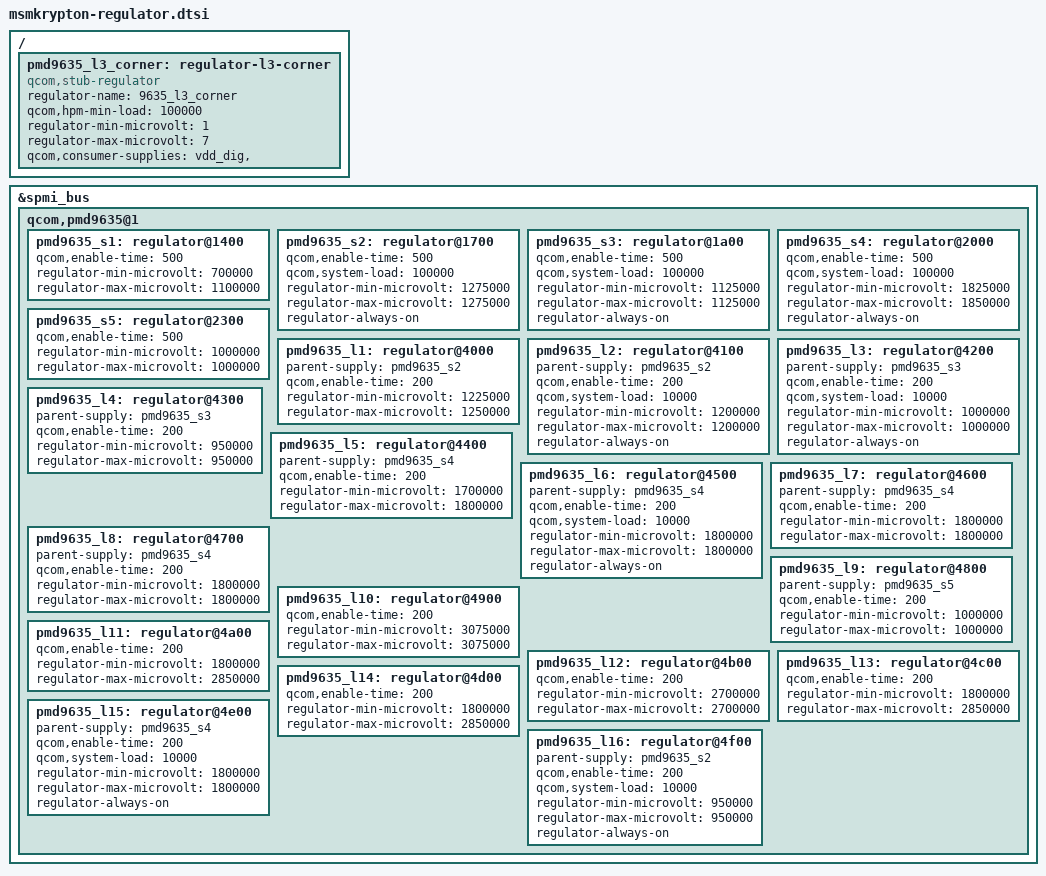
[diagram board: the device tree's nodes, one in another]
/* Copyright (c) 2013, The Linux Foundation. All rights reserved.
 *
 * This program is free software; you can redistribute it and/or modify
 * it under the terms of the GNU General Public License version 2 and
 * only version 2 as published by the Free Software Foundation.
 *
 * This program is distributed in the hope that it will be useful,
 * but WITHOUT ANY WARRANTY; without even the implied warranty of
 * MERCHANTABILITY or FITNESS FOR A PARTICULAR PURPOSE.  See the
 * GNU General Public License for more details.
 */

/* Stub Regulators */
/ {
	pmd9635_l3_corner: regulator-l3-corner {
		compatible = "qcom,stub-regulator";
		regulator-name = "9635_l3_corner";
		qcom,hpm-min-load = <100000>;
		regulator-min-microvolt = <1>;
		regulator-max-microvolt = <7>;
		qcom,consumer-supplies = "vdd_dig", "";
	};
};

&spmi_bus {
	qcom,pmd9635@1{
		pmd9635_s1: regulator@1400 {
			status = "okay";
			qcom,enable-time = <500>;
			regulator-min-microvolt = <700000>;
			regulator-max-microvolt = <1100000>;
		};

		pmd9635_s2: regulator@1700 {
			status = "okay";
			qcom,enable-time = <500>;
			qcom,system-load = <100000>;
			regulator-min-microvolt = <1275000>;
			regulator-max-microvolt = <1275000>;
			regulator-always-on;
		};

		pmd9635_s3: regulator@1a00 {
			status = "okay";
			qcom,enable-time = <500>;
			qcom,system-load = <100000>;
			regulator-min-microvolt = <1125000>;
			regulator-max-microvolt = <1125000>;
			regulator-always-on;
		};

		pmd9635_s4: regulator@2000 {
			status = "okay";
			qcom,enable-time = <500>;
			qcom,system-load = <100000>;
			regulator-min-microvolt = <1825000>;
			regulator-max-microvolt = <1850000>;
			regulator-always-on;
		};

		pmd9635_s5: regulator@2300 {
			status = "okay";
			qcom,enable-time = <500>;
			regulator-min-microvolt = <1000000>;
			regulator-max-microvolt = <1000000>;
		};

		pmd9635_l1: regulator@4000 {
			status = "okay";
			parent-supply = <&pmd9635_s2>;
			qcom,enable-time = <200>;
			regulator-min-microvolt = <1225000>;
			regulator-max-microvolt = <1250000>;
		};

		pmd9635_l2: regulator@4100 {
			status = "okay";
			parent-supply = <&pmd9635_s2>;
			qcom,enable-time = <200>;
			qcom,system-load = <10000>;
			regulator-min-microvolt = <1200000>;
			regulator-max-microvolt = <1200000>;
			regulator-always-on;
		};

		pmd9635_l3: regulator@4200 {
			status = "okay";
			parent-supply = <&pmd9635_s3>;
			qcom,enable-time = <200>;
			qcom,system-load = <10000>;
			regulator-min-microvolt = <1000000>;
			regulator-max-microvolt = <1000000>;
			regulator-always-on;
		};

		pmd9635_l4: regulator@4300 {
			status = "okay";
			parent-supply = <&pmd9635_s3>;
			qcom,enable-time = <200>;
			regulator-min-microvolt = <950000>;
			regulator-max-microvolt = <950000>;
		};

		pmd9635_l5: regulator@4400 {
			status = "okay";
			parent-supply = <&pmd9635_s4>;
			qcom,enable-time = <200>;
			regulator-min-microvolt = <1700000>;
			regulator-max-microvolt = <1800000>;
		};

		pmd9635_l6: regulator@4500 {
			status = "okay";
			parent-supply = <&pmd9635_s4>;
			qcom,enable-time = <200>;
			qcom,system-load = <10000>;
			regulator-min-microvolt = <1800000>;
			regulator-max-microvolt = <1800000>;
			regulator-always-on;
		};

		pmd9635_l7: regulator@4600 {
			status = "okay";
			parent-supply = <&pmd9635_s4>;
			qcom,enable-time = <200>;
			regulator-min-microvolt = <1800000>;
			regulator-max-microvolt = <1800000>;
		};

		pmd9635_l8: regulator@4700 {
			status = "okay";
			parent-supply = <&pmd9635_s4>;
			qcom,enable-time = <200>;
			regulator-min-microvolt = <1800000>;
			regulator-max-microvolt = <1800000>;
		};

		pmd9635_l9: regulator@4800 {
			status = "okay";
			parent-supply = <&pmd9635_s5>;
			qcom,enable-time = <200>;
			regulator-min-microvolt = <1000000>;
			regulator-max-microvolt = <1000000>;
		};

		pmd9635_l10: regulator@4900 {
			status = "okay";
			qcom,enable-time = <200>;
			regulator-min-microvolt = <3075000>;
			regulator-max-microvolt = <3075000>;
		};

		pmd9635_l11: regulator@4a00 {
			status = "okay";
			qcom,enable-time = <200>;
			regulator-min-microvolt = <1800000>;
			regulator-max-microvolt = <2850000>;
		};

		pmd9635_l12: regulator@4b00 {
			status = "okay";
			qcom,enable-time = <200>;
			regulator-min-microvolt = <2700000>;
			regulator-max-microvolt = <2700000>;
		};

		pmd9635_l13: regulator@4c00 {
			status = "okay";
			qcom,enable-time = <200>;
			regulator-min-microvolt = <1800000>;
			regulator-max-microvolt = <2850000>;
		};

		pmd9635_l14: regulator@4d00 {
			status = "okay";
			qcom,enable-time = <200>;
			regulator-min-microvolt = <1800000>;
			regulator-max-microvolt = <2850000>;
		};

		pmd9635_l15: regulator@4e00 {
			status = "okay";
			parent-supply = <&pmd9635_s4>;
			qcom,enable-time = <200>;
			qcom,system-load = <10000>;
			regulator-min-microvolt = <1800000>;
			regulator-max-microvolt = <1800000>;
			regulator-always-on;
		};

		pmd9635_l16: regulator@4f00 {
			status = "okay";
			parent-supply = <&pmd9635_s2>;
			qcom,enable-time = <200>;
			qcom,system-load = <10000>;
			regulator-min-microvolt = <950000>;
			regulator-max-microvolt = <950000>;
			regulator-always-on;
		};
	};
};
